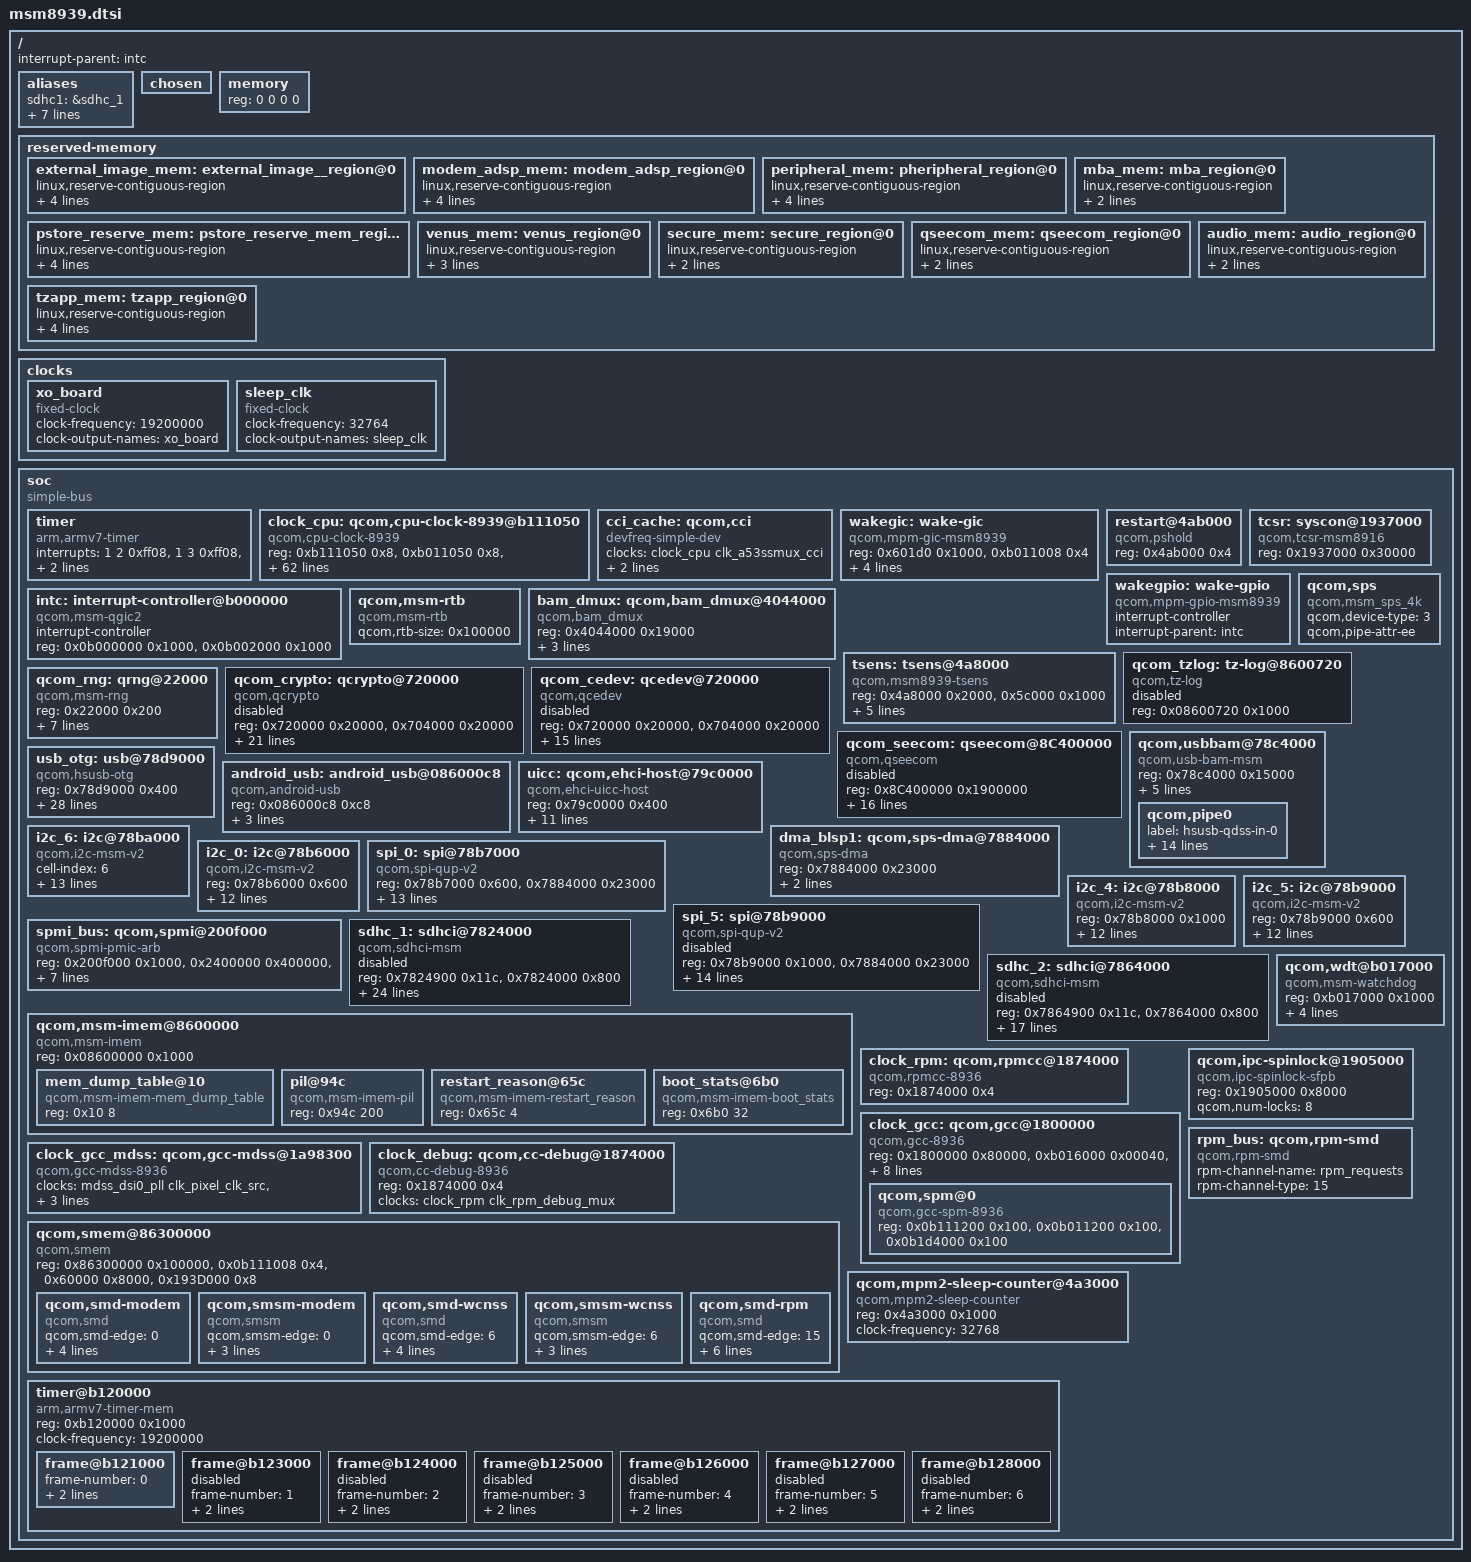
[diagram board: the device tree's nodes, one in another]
// SPDX-License-Identifier: GPL-2.0-only
/*
 * Copyright (c) 2013-2015, The Linux Foundation. All rights reserved.
 */


#include <dt-bindings/interrupt-controller/arm-gic.h>

/ {
	interrupt-parent = <&intc>;

	#address-cells = <2>;
	#size-cells = <2>;

	aliases {
		sdhc1 = &sdhc_1; /* SDC1 eMMC slot */
		sdhc2 = &sdhc_2; /* SDC2 SD card slot */
		/* smdtty devices */
		//smd0 = &smdtty_ds;
		//smd1 = &smdtty_apps_fm;
		//smd2 = &smdtty_apps_riva_bt_acl;
		//smd3 = &smdtty_apps_riva_bt_cmd;
		//smd5 = &smdtty_apps_riva_ant_cmd;
		//smd6 = &smdtty_apps_riva_ant_data;
		//smd7 = &smdtty_data1;
		//smd8 = &smdtty_data4;
		//smd11 = &smdtty_data11;
		//smd21 = &smdtty_data21;
		//smd36 = &smdtty_loopback;
		i2c0 = &i2c_0;
		i2c4 = &i2c_4;
		i2c5 = &i2c_5;
		i2c6 = &i2c_6;
		spi0 = &spi_0;
		spi5 = &spi_5;
	};

	chosen { };

	memory {
		device_type = "memory";
		/* We expect the bootloader to fill in the reg */
		reg = <0 0 0 0>;
	};

	reserved-memory {
		#address-cells = <2>;
		#size-cells = <2>;
		ranges;

		external_image_mem: external_image__region@0 {
			linux,reserve-contiguous-region;
			linux,reserve-region;
			linux,remove-completely;
			reg = <0x0 0x86000000 0x0 0x0800000>;
			label = "external_image_mem";
		};

		modem_adsp_mem: modem_adsp_region@0 {
			linux,reserve-contiguous-region;
			linux,reserve-region;
			linux,remove-completely;
			reg = <0x0 0x86800000 0x0 0x05600000>;
			label = "modem_adsp_mem";
		};

		peripheral_mem: pheripheral_region@0 {
			linux,reserve-contiguous-region;
			linux,reserve-region;
			linux,remove-completely;
			reg = <0x0 0x8be00000 0x0 0x0600000>;
			label = "peripheral_mem";
		};

		pstore_reserve_mem: pstore_reserve_mem_region@0 {
			linux,reserve-contiguous-region;
			linux,reserve-region;
			linux,remove-completely;
			reg = <0x0 0xdfe00000 0x0 0x00200000>;
			label = "pstore_reserve_mem";
		};

		mba_mem: mba_region@0 {
			linux,reserve-contiguous-region;
			reg = <0 0 0 0x0200000>;
			label = "mba_mem";
		};

		venus_mem: venus_region@0 {
			linux,reserve-contiguous-region;
			linux,memory-limit = <0x90000000>;
			reg = <0 0 0 0x0500000>;
			label = "venus_mem";
		};

		secure_mem: secure_region@0 {
			linux,reserve-contiguous-region;
			reg = <0 0 0 0x6D00000>;
			label = "secure_mem";
		};

		qseecom_mem: qseecom_region@0 {
			linux,reserve-contiguous-region;
			reg = <0 0 0 0x1900000>;
			label = "qseecom_mem";
		};

		audio_mem: audio_region@0 {
			linux,reserve-contiguous-region;
			reg = <0 0 0 0x314000>;
			label = "audio_mem";
		};

		tzapp_mem: tzapp_region@0 {
			linux,reserve-contiguous-region;
			linux,reserve-region;
			linux,remove-completely;
			reg = <0 0x8C400000 0 0x1900000>;
			label = "tzapp_mem";
		};
	};

	clocks {
		xo_board {
			compatible = "fixed-clock";
			#clock-cells = <0>;
			clock-frequency = <19200000>;
			clock-output-names = "xo_board";
		};

		sleep_clk {
			compatible = "fixed-clock";
			#clock-cells = <0>;
			clock-frequency = <32764>;
			clock-output-names = "sleep_clk";
		};
	};

	soc: soc {
		#address-cells = <1>;
		#size-cells = <1>;
		ranges = <0 0 0 0xffffffff>;
		compatible = "simple-bus";

	timer {
		compatible = "arm,armv7-timer";
		interrupts = <1 2 0xff08>,
			     <1 3 0xff08>,
			     <1 4 0xff08>,
			     <1 1 0xff08>;
		clock-frequency = <19200000>;
	};

	clock_cpu: qcom,cpu-clock-8939@b111050 {
		compatible = "qcom,cpu-clock-8939";
		reg =   <0xb111050 0x8>,
			<0xb011050 0x8>,
			<0xb1d1050 0x8>,
			<0x5800c   0x8>,
			<0x58000   0x8>,
			<0x58004   0x8>;
		reg-names = "apcs-c0-rcg-base", "apcs-c1-rcg-base",
				"apcs-cci-rcg-base", "efuse", "efuse1",
				"efuse2";
		vdd-c0-supply = <&apc_vreg_corner>;
		vdd-c1-supply = <&apc_vreg_corner>;
		vdd-cci-supply = <&apc_vreg_corner>;
		clocks = <&clock_gcc clk_gpll0_ao>,
			 <&clock_gcc clk_a53ss_c0_pll>,
			 <&clock_gcc clk_gpll0_ao>,
			 <&clock_gcc clk_a53ss_c1_pll>,
			 <&clock_gcc clk_gpll0_ao>,
			 <&clock_gcc clk_a53ss_cci_pll>;
		clock-names = "clk-c0-4", "clk-c0-5",
				"clk-c1-4", "clk-c1-5",
				"clk-cci-4", "clk-cci-5";
		qcom,speed0-bin-v0-c0 =
			<          0 0>,
			<  400000000 3>,
			<  500000000 9>,
			<  800000000 12>,
			<  998400000 17>,
			< 1113600000 20>,
			< 1209600000 21>;

		qcom,speed0-bin-v0-c1 =
			<          0 0>,
			<  400000000 3>,
			<  800000000 9>,
			<  960000000 12>,
			< 1113600000 14>,
			< 1344000000 17>;

		qcom,speed0-bin-v0-cci =
			<          0 0>,
			<  200000000 3>,
			<  300000000 9>,
			<  400000000 15>,
			<  600000000 17>;

		qcom,speed2-bin-v0-c0 =
			<          0 0>,
			<  400000000 3>,
			<  500000000 9>,
			<  800000000 12>,
			<  998400000 17>,
			< 1113600000 20>,
			< 1209600000 22>;

		qcom,speed2-bin-v0-c1 =
			<          0 0>,
			<  400000000 3>,
			<  800000000 9>,
			<  960000000 12>,
			< 1113600000 14>,
			< 1344000000 17>,
			< 1459200000 20>,
			< 1497600000 21>;

		qcom,speed2-bin-v0-cci =
			<          0 0>,
			<  200000000 3>,
			<  300000000 9>,
			<  400000000 15>,
			<  600000000 17>;

		qcom,speed2-bin-v2-c0 =
			<          0 0>,
			<  400000000 3>,
			<  500000000 9>,
			<  800000000 12>,
			<  998400000 17>,
			< 1113600000 20>,
			< 1209600000 22>;

		qcom,speed2-bin-v2-c1 =
			<          0 0>,
			<  400000000 3>,
			<  800000000 9>,
			<  960000000 12>,
			< 1113600000 14>,
			< 1344000000 17>,
			< 1459200000 20>;

		qcom,speed2-bin-v2-cci =
			<          0 0>,
			<  200000000 3>,
			<  300000000 9>,
			<  400000000 15>,
			<  600000000 17>;

		qcom,speed4-bin-v0-c0 =
			<          0 0>,
			<  400000000 3>,
			<  500000000 9>,
			<  800000000 12>,
			<  998400000 17>,
			< 1113600000 20>,
			< 1209600000 26>;

		qcom,speed4-bin-v0-c1 =
			<          0 0>,
			<  400000000 3>,
			<  800000000 9>,
			<  960000000 12>,
			< 1113600000 14>,
			< 1344000000 17>,
			< 1459200000 20>,
			< 1497600000 21>,
			< 1651200000 26>;

		qcom,speed4-bin-v0-cci =
			<          0 0>,
			<  200000000 3>,
			<  300000000 9>,
			<  400000000 15>,
			<  600000000 17>;

		qcom,speed5-bin-v0-c0 =
			<          0 0>,
			<  400000000 3>,
			<  500000000 9>,
			<  800000000 12>,
			<  998400000 17>,
			< 1113600000 20>,
			< 1209600000 23>;

		qcom,speed5-bin-v0-c1 =
			<          0 0>,
			<  400000000 3>,
			<  800000000 9>,
			<  960000000 12>,
			< 1113600000 14>,
			< 1344000000 17>,
			< 1459200000 18>,
			< 1497600000 21>,
			< 1651200000 26>;

		qcom,speed5-bin-v0-cci =
			<          0 0>,
			<  200000000 3>,
			<  300000000 9>,
			<  400000000 15>,
			<  600000000 17>;

		qcom,speed5-bin-v6-c0 =
			<          0 0>,
			<  400000000 3>,
			<  500000000 9>,
			<  800000000 12>,
			<  998400000 17>,
			< 1113600000 20>,
			< 1209600000 23>;

		qcom,speed5-bin-v6-c1 =
			<          0 0>,
			<  400000000 3>,
			<  800000000 9>,
			<  960000000 12>,
			< 1113600000 14>,
			< 1344000000 17>,
			< 1459200000 18>,
			< 1497600000 21>,
			< 1651200000 26>;

		qcom,speed5-bin-v6-cci =
			<          0 0>,
			<  200000000 3>,
			<  300000000 9>,
			<  400000000 15>,
			<  600000000 17>;

		#clock-cells = <1>;
	};

	cci_cache: qcom,cci {
		compatible = "devfreq-simple-dev";
		clock-names = "devfreq_clk";
		clocks = <&clock_cpu clk_a53ssmux_cci>;
		governor = "cpufreq";
		freq-tbl-khz =
			<  200000 >,
			<  297600 >,
			<  400000 >,
			<  595200 >;
	};
#if 0
	cpubw: qcom,cpubw {
		label = "cpubw";
		compatible = "qcom,devbw";
		governor = "cpufreq";
		qcom,src-dst-ports = <1 512>;
		qcom,active-only;
		qcom,bw-tbl =
			<  1525 /*  100   MHz */ >,
			<  2636 /*  172.8 MHz */ >,
			<  3955 /*  259.2 MHz */ >,
			<  5346 /*  350.4 MHz */ >,
			<  5712 /*  374.4 MHz */ >,
			<  6079 /*  398.4 MHz */ >;
	};

	mincpubw: qcom,mincpubw {
		label = "mincpubw";
		compatible = "qcom,devbw";
		governor = "powersave";
		qcom,src-dst-ports = <1 512>;
		qcom,active-only;
		qcom,bw-tbl =
			<  1525 /*  100   MHz */ >,
			<  2636 /*  172.8 MHz */ >,
			<  3955 /*  259.2 MHz */ >,
			<  5346 /*  350.4 MHz */ >,
			<  5712 /*  374.4 MHz */ >,
			<  6079 /*  398.4 MHz */ >;
	};

	devfreq-cpufreq {
		cpubw-cpufreq {
		target-dev = <&cpubw>;
		cpu-to-dev-map-0 =
			<  200000  1525 >,
			<  800000  2636 >,
			< 1113600  5346 >,
			< 1651200  6079 >;
		cpu-to-dev-map-4 =
			<  200000  1525 >,
			<  499200  2636 >,
			<  800000  5346 >,
			< 1209600  6079 >;
		};

		mincpubw-cpufreq {
		target-dev = <&mincpubw>;
		cpu-to-dev-map-0 =
			< 1113600 2636 >,
			< 1651200 5346 >;
		cpu-to-dev-map-4 =
			<  998400 2636 >,
			< 1209600 5346 >;
		};

		cci-cpufreq {
		target-dev = <&cci_cache>;
		cpu-to-dev-map-0 =
			<  200000  200000 >,
			<  400000  200000 >,
			< 1113600  297000 >,
			< 1651200  595200 >;
		cpu-to-dev-map-4 =
			<  200000 200000 >,
			<  400000 200000 >,
			<  800000 297600 >,
			< 1209600 595200 >;
		};
	};

	qcom,msm-cpufreq {
		compatible = "qcom,msm-cpufreq";
		clock-names = "l2_clk", "cpu0_clk", "cpu1_clk", "cpu2_clk",
				"cpu3_clk", "cpu4_clk", "cpu5_clk",
				"cpu6_clk", "cpu7_clk";
		clocks = <&clock_cpu clk_a53ssmux_cci>,
			 <&clock_cpu clk_a53ssmux_bc>,
			 <&clock_cpu clk_a53ssmux_bc>,
			 <&clock_cpu clk_a53ssmux_bc>,
			 <&clock_cpu clk_a53ssmux_bc>,
			 <&clock_cpu clk_a53ssmux_lc>,
			 <&clock_cpu clk_a53ssmux_lc>,
			 <&clock_cpu clk_a53ssmux_lc>,
			 <&clock_cpu clk_a53ssmux_lc>;

		qcom,governor-per-policy;

		qcom,cpufreq-table-0 =
			 <  200000 >,
			 <  345600 >,
			 <  400000 >,
			 <  533330 >,
			 <  800000 >,
                         <  960000 >,
			 < 1113600 >,
			 < 1344000 >,
			 < 1459200 >,
			 < 1497600 >,
			 < 1651200 >;

		qcom,cpufreq-table-4 =
			 <  200000 >,
			 <  249600 >,
			 <  400000 >,
			 <  499200 >,
			 <  800000 >,
			 <  998400 >,
			 < 1113600 >,
			 < 1209600 >;
	};

	cpu-pmu {
		compatible = "arm,armv8-pmuv3";
		qcom,irq-is-percpu;
		interrupts = <1 7 0xff00>;
	};

	jtag_fuse: jtagfuse@5e01c {
		compatible = "qcom,jtag-fuse-v2";
		reg = <0x5e01c 0x8>;
		reg-names = "fuse-base";
	};

	sn_fuse: snfuse@0x5c008 {
		compatible = "qcom,sn-fuse";
		reg = <0x5c008 0x4>;
		reg-names = "sn-base";
	};

	sec_boot_fuse: secbootfuse@0x5c098 {
		compatible = "qcom,sec-boot-fuse";
		reg = <0x5c098 0x4>;
		reg-names = "sec-boot-base";
	};
	jtag_mm0: jtagmm@8fc000 {
		compatible = "qcom,jtagv8-mm";
		reg = <0x8fc000 0x1000>,
		      <0x8f0000 0x1000>;
		reg-names = "etm-base", "debug-base";

		clocks = <&clock_rpm clk_qdss_clk>,
		         <&clock_rpm clk_qdss_a_clk>;
		clock-names = "core_clk", "core_a_clk";

		qcom,coresight-jtagmm-cpu = <&CPU0>;
	};

	jtag_mm1: jtagmm@8fd000 {
		compatible = "qcom,jtagv8-mm";
		reg = <0x8fd000 0x1000>,
		      <0x8f2000 0x1000>;
		reg-names = "etm-base", "debug-base";

		clocks = <&clock_rpm clk_qdss_clk>,
		         <&clock_rpm clk_qdss_a_clk>;
		clock-names = "core_clk", "core_a_clk";

		qcom,coresight-jtagmm-cpu = <&CPU1>;
	};

	jtag_mm2: jtagmm@8fe000 {
		compatible = "qcom,jtagv8-mm";
		reg = <0x8fe000 0x1000>,
		      <0x8f4000 0x1000>;
		reg-names = "etm-base", "debug-base";

		clocks = <&clock_rpm clk_qdss_clk>,
		         <&clock_rpm clk_qdss_a_clk>;
		clock-names = "core_clk", "core_a_clk";

		qcom,coresight-jtagmm-cpu = <&CPU2>;
	};

	jtag_mm3: jtagmm@8ff000 {
		compatible = "qcom,jtagv8-mm";
		reg = <0x8ff000 0x1000>,
		      <0x8f6000 0x1000>;
		reg-names = "etm-base", "debug-base";

		clocks = <&clock_rpm clk_qdss_clk>,
		         <&clock_rpm clk_qdss_a_clk>;
		clock-names = "core_clk", "core_a_clk";

		qcom,coresight-jtagmm-cpu = <&CPU3>;
	};

	jtag_mm4: jtagmm@8dc000 {
		compatible = "qcom,jtagv8-mm";
		reg = <0x8dc000 0x1000>,
		      <0x8d0000 0x1000>;
		reg-names = "etm-base", "debug-base";

		clocks = <&clock_rpm clk_qdss_clk>,
		         <&clock_rpm clk_qdss_a_clk>;
		clock-names = "core_clk", "core_a_clk";

		qcom,coresight-jtagmm-cpu = <&CPU4>;
	};

	jtag_mm5: jtagmm@8dd000 {
		compatible = "qcom,jtagv8-mm";
		reg = <0x8dd000 0x1000>,
		      <0x8d2000 0x1000>;
		reg-names = "etm-base", "debug-base";

		clocks = <&clock_rpm clk_qdss_clk>,
		         <&clock_rpm clk_qdss_a_clk>;
		clock-names = "core_clk", "core_a_clk";

		qcom,coresight-jtagmm-cpu = <&CPU5>;
	};

	jtag_mm6: jtagmm@8de000 {
		compatible = "qcom,jtagv8-mm";
		reg = <0x8de000 0x1000>,
		      <0x8d4000 0x1000>;
		reg-names = "etm-base", "debug-base";

		clocks = <&clock_rpm clk_qdss_clk>,
		         <&clock_rpm clk_qdss_a_clk>;
		clock-names = "core_clk", "core_a_clk";

		qcom,coresight-jtagmm-cpu = <&CPU6>;
	};

	jtag_mm7: jtagmm@8df000 {
		compatible = "qcom,jtagv8-mm";
		reg = <0x8df000 0x1000>,
		      <0x8d6000 0x1000>;
		reg-names = "etm-base", "debug-base";

		clocks = <&clock_rpm clk_qdss_clk>,
		         <&clock_rpm clk_qdss_a_clk>;
		clock-names = "core_clk", "core_a_clk";

		qcom,coresight-jtagmm-cpu = <&CPU7>;
	};

	qcom,msm-thermal {
		qcom,core-control-mask = <0xFF>;
		qcom,freq-mitigation-control-mask = <0xFF>;
	};
#endif
	wakegic: wake-gic {
		compatible = "qcom,mpm-gic-msm8939", "qcom,mpm-gic";
		reg = <0x601d0 0x1000>, /* MSM_RPM_MPM_BASE 4K */
		      <0xb011008 0x4>;
		reg-names = "vmpm", "ipc";
		qcom,num-mpm-irqs = <96>;
		interrupts = <GIC_SPI 171 IRQ_TYPE_EDGE_RISING>;
		interrupt-controller;
		interrupt-parent = <&intc>;
		#interrupt-cells = <3>;
	};

	restart@4ab000 {
		compatible = "qcom,pshold";
		reg = <0x4ab000 0x4>;
		reg-names = "pshold-base";
	};

	tcsr: syscon@1937000 {
		compatible = "qcom,tcsr-msm8916", "syscon";
		reg = <0x1937000 0x30000>;
		};

	wakegpio: wake-gpio {
		compatible = "qcom,mpm-gpio-msm8939", "qcom,mpm-gpio";
		interrupt-controller;
		interrupt-parent = <&intc>;
		#interrupt-cells = <2>;
	};

	intc: interrupt-controller@b000000 {
			compatible = "qcom,msm-qgic2";
			interrupt-controller;
			#interrupt-cells = <3>;
			reg = <0x0b000000 0x1000>, <0x0b002000 0x1000>;
		};

	qcom,msm-rtb {
		compatible = "qcom,msm-rtb";
		qcom,rtb-size = <0x100000>;
	};

	qcom,sps {
		compatible = "qcom,msm_sps_4k";
		qcom,device-type = <3>;
		qcom,pipe-attr-ee;
	};

	bam_dmux: qcom,bam_dmux@4044000 {
		compatible = "qcom,bam_dmux";
		reg = <0x4044000 0x19000>;
		interrupts = <0 29 1>;
		qcom,rx-ring-size = <32>;
		qcom,max-rx-mtu = <4096>;
	};

	tsens: tsens@4a8000 {
		compatible = "qcom,msm8939-tsens";
		reg = <0x4a8000 0x2000>,
		      <0x5c000  0x1000>;
		reg-names = "tsens_physical", "tsens_eeprom_physical";
		interrupts = <0 184 0>;
		interrupt-names = "tsens-upper-lower";
		qcom,sensors = <9>;
		qcom,slope = <2911 2789 2906 2763 2922 2867 2833 2838 2840>;
		qcom,sensor-id = <0 1 2 3 5 6 7 8 9>;
	};

	qcom_tzlog: tz-log@8600720 {
		compatible = "qcom,tz-log";
		reg = <0x08600720 0x1000>;
		status = "disabled";
	};

	qcom_rng: qrng@22000 {
		compatible = "qcom,msm-rng";
		reg = <0x22000 0x200>;
		qcom,msm-rng-iface-clk;
		qcom,msm-bus,name = "msm-rng-noc";
		qcom,msm-bus,num-cases = <2>;
		qcom,msm-bus,num-paths = <1>;
		qcom,msm-bus,vectors-KBps =
				<1 618 0 0>,		/* No vote */
				<1 618 0 800>;		/* 100 MB/s */
		clocks = <&clock_gcc clk_gcc_prng_ahb_clk>;
		clock-names = "iface_clk";
		status = "ok";
	};

	qcom_crypto: qcrypto@720000 {
		compatible = "qcom,qcrypto";
		reg = <0x720000 0x20000>,
		      <0x704000 0x20000>;
		reg-names = "crypto-base","crypto-bam-base";
		interrupts = <0 207 0>;
		qcom,bam-pipe-pair = <2>;
		qcom,ce-hw-instance = <0>;
		qcom,ce-device = <0>;
		qcom,clk-mgmt-sus-res;
		qcom,msm-bus,name = "qcrypto-noc";
		qcom,msm-bus,num-cases = <2>;
		qcom,msm-bus,num-paths = <1>;
		qcom,msm-bus,vectors-KBps =
				<55 512 0 0>,
				<55 512 393600 800000>; /* 49.2MHz & 100MHz */
		clocks = <&clock_gcc clk_crypto_clk_src>,
			 <&clock_gcc clk_gcc_crypto_clk>,
			 <&clock_gcc clk_gcc_crypto_ahb_clk>,
			 <&clock_gcc clk_gcc_crypto_axi_clk>;
		clock-names = "core_clk_src", "core_clk",
				"iface_clk", "bus_clk";
                qcom,use-sw-aes-cbc-ecb-ctr-algo;
                qcom,use-sw-aes-xts-algo;
                qcom,use-sw-aes-ccm-algo;
                qcom,use-sw-ahash-algo;
		qcom,use-sw-hmac-algo;
		qcom,use-sw-aead-algo;
		status = "disabled";
		qcom,ce-opp-freq = <100000000>;
	};

	qcom_cedev: qcedev@720000 {
		compatible = "qcom,qcedev";
		reg = <0x720000 0x20000>,
		      <0x704000 0x20000>;
		reg-names = "crypto-base","crypto-bam-base";
		interrupts = <0 207 0>;
		qcom,bam-pipe-pair = <1>;
		qcom,ce-hw-instance = <0>;
		qcom,ce-device = <0>;
		qcom,ce-hw-shared;
		qcom,msm-bus,name = "qcedev-noc";
		qcom,msm-bus,num-cases = <2>;
		qcom,msm-bus,num-paths = <1>;
		qcom,msm-bus,vectors-KBps =
				<55 512 0 0>,
				<55 512 393600 800000>; /* 49.2MHz & 100MHz */
		clocks = <&clock_gcc clk_crypto_clk_src>,
			 <&clock_gcc clk_gcc_crypto_clk>,
			 <&clock_gcc clk_gcc_crypto_ahb_clk>,
			 <&clock_gcc clk_gcc_crypto_axi_clk>;
		clock-names = "core_clk_src", "core_clk",
				"iface_clk", "bus_clk";
		status = "disabled";
		qcom,ce-opp-freq = <100000000>;
	};

	qcom_seecom: qseecom@8C400000 {
		compatible = "qcom,qseecom";
		reg = <0x8C400000 0x1900000>;
		reg-names = "secapp-region";
		qcom,disk-encrypt-pipe-pair = <2>;
		qcom,hlos-ce-hw-instance = <0>;
		qcom,qsee-ce-hw-instance = <0>;
		qcom,msm-bus,name = "qseecom-noc";
		qcom,msm-bus,num-cases = <4>;
		qcom,msm-bus,num-paths = <1>;
		qcom,support-bus-scaling;
		qcom,support-fde;
		qcom,msm-bus,vectors-KBps =
				<55 512 0 0>,
				<55 512 0 0>,
				<55 512 120000 1200000>,
				<55 512 393600 3936000>;
		clocks = <&clock_gcc clk_crypto_clk_src>,
			 <&clock_gcc clk_gcc_crypto_clk>,
			 <&clock_gcc clk_gcc_crypto_ahb_clk>,
			 <&clock_gcc clk_gcc_crypto_axi_clk>;
		clock-names = "core_clk_src", "core_clk",
				"iface_clk", "bus_clk";
		status = "disabled";
		qcom,ce-opp-freq = <100000000>;
	};

	qcom,usbbam@78c4000 {
		compatible = "qcom,usb-bam-msm";
		reg = <0x78c4000 0x15000>;
		reg-names = "hsusb";
		interrupts = <0 135 0>;
		interrupt-names = "hsusb";
		qcom,usb-bam-num-pipes = <2>;
		qcom,usb-bam-fifo-baseaddr = <0x08603800>;
		qcom,ignore-core-reset-ack;
		qcom,disable-clk-gating;

		qcom,pipe0 {
			label = "hsusb-qdss-in-0";
			qcom,usb-bam-mem-type = <3>;
			qcom,bam-type = <1>;
			qcom,dir = <1>;
			qcom,pipe-num = <0>;
			qcom,peer-bam = <1>;
			qcom,src-bam-physical-address = <0x884000>;
			qcom,src-bam-pipe-index = <0>;
			qcom,dst-bam-physical-address = <0x78c4000>;
			qcom,dst-bam-pipe-index = <0>;
			qcom,data-fifo-offset = <0x0>;
			qcom,data-fifo-size = <0x600>;
			qcom,descriptor-fifo-offset = <0x600>;
			qcom,descriptor-fifo-size = <0x200>;
			qcom,reset-bam-on-connect;
		};
	};

	usb_otg: usb@78d9000 {
		compatible = "qcom,hsusb-otg";

		reg = <0x78d9000 0x400>;
		reg-names = "core";
		interrupts = <0 134 0>,<0 140 0>;
		interrupt-names = "core_irq", "async_irq";

		hsusb_vdd_dig-supply = <&pm8916_s2_corner>;
		HSUSB_1p8-supply = <&pm8916_l7>;
		HSUSB_3p3-supply = <&pm8916_l13>;
		qcom,vdd-voltage-level = <1 5 7>;

		qcom,hsusb-otg-phy-init-seq =
			<0x44 0x80 0x6B 0x81 0x24 0x82 0x13 0x83 0xffffffff>;
		qcom,hsusb-otg-phy-type = <2>;
		qcom,hsusb-otg-mode = <1>;
		qcom,hsusb-otg-otg-control = <2>;
		qcom,hsusb-otg-disable-reset;
		qcom,dp-manual-pullup;
		qcom,hsusb-otg-mpm-dpsehv-int = <49>;
		qcom,hsusb-otg-mpm-dmsehv-int = <58>;

		qcom,msm-bus,name = "usb2";
		qcom,msm-bus,num-cases = <3>;
		qcom,msm-bus,num-paths = <1>;
		qcom,msm-bus,vectors-KBps =
				<87 512 0 0>,
				<87 512 80000 0>,
				<87 512 6000  6000>;
		clocks = <&clock_gcc clk_gcc_usb_hs_ahb_clk>,
			 <&clock_gcc clk_gcc_usb_hs_system_clk>,
			 <&clock_gcc clk_gcc_usb2a_phy_sleep_clk>,
			 <&clock_rpm clk_bimc_usb_a_clk>,
			 <&clock_rpm clk_snoc_usb_a_clk>,
			 <&clock_rpm clk_pcnoc_usb_a_clk>,
			 <&clock_rpm clk_xo_otg_clk>;
		clock-names = "iface_clk", "core_clk", "sleep_clk",
				"bimc_clk", "snoc_clk", "pcnoc_clk",
				"xo";
		qcom,bus-clk-rate = <331200000 200000000 100000000>;
	};

	android_usb: android_usb@086000c8 {
		compatible = "qcom,android-usb";
		reg = <0x086000c8 0xc8>;
		qcom,pm-qos-latency = <2 1001 12701>;
		qcom,streaming-func = "rndis","mtp";
		qcom,android-usb-uicc-nluns = /bits/ 8 <1>;
	};

	uicc: qcom,ehci-host@79c0000 {
		compatible = "qcom,ehci-uicc-host";
		reg = <0x79c0000 0x400>;
		interrupts = <0 132 0>;

		clocks = <&clock_gcc clk_gcc_usb_fs_ahb_clk>,
			 <&clock_gcc clk_gcc_usb_fs_system_clk>,
			 <&clock_gcc clk_gcc_usb_fs_ic_clk>;
		clock-names = "iface_clk", "core_clk", "alt_core_clk";

                pinctrl-names = "uicc_active", "uicc_sleep";
                pinctrl-0 = <&uicc_active>;
                pinctrl-1 = <&uicc_sleep>;

		qcom,msm-bus,name = "uicc";
		qcom,msm-bus,num-cases = <2>;
		qcom,msm-bus,num-paths = <1>;
		qcom,msm-bus,vectors-KBps =
				<93 512 0 0>,
				<93 512 12000 192000>;
	};

	dma_blsp1: qcom,sps-dma@7884000 { /* BLSP1 */
		#dma-cells = <4>;
		compatible = "qcom,sps-dma";
		reg = <0x7884000 0x23000>;
		interrupts = <0 238 0>;
		qcom,summing-threshold = <10>;
	};

	i2c_6: i2c@78ba000 { /* BLSP1 QUP6 */
		compatible = "qcom,i2c-msm-v2";
		#address-cells=<1>;
		#size-cells=<0>;
		cell-index = <6>;
		reg-names = "qup_phys_addr";
		reg = <0x78ba000 0x1000>;
		interrupt-names = "qup_irq";
		interrupts = <0 100 0>;
		clocks = <&clock_gcc clk_gcc_blsp1_ahb_clk>,
			 <&clock_gcc clk_gcc_blsp1_qup6_i2c_apps_clk>;
		clock-names = "iface_clk", "core_clk";
		qcom,clk-freq-out = <400000>;
		qcom,clk-freq-in  = <19200000>;
		pinctrl-names = "i2c_active", "i2c_sleep";
		pinctrl-0 = <&i2c_6_active>;
		pinctrl-1 = <&i2c_6_sleep>;
		qcom,noise-rjct-scl = <0>;
		qcom,noise-rjct-sda = <0>;
		dmas = <&dma_blsp1 14 64 0x20000020 0x20>,
			<&dma_blsp1 15 32 0x20000020 0x20>;
		dma-names = "tx", "rx";
		qcom,master-id = <86>;
	};

	i2c_0: i2c@78b6000 { /* BLSP1 QUP2 */
		compatible = "qcom,i2c-msm-v2";
		#address-cells = <1>;
		#size-cells = <0>;
		reg-names = "qup_phys_addr";
		reg = <0x78b6000 0x600>;
		interrupt-names = "qup_irq";
		interrupts = <0 96 0>;
		clocks = <&clock_gcc clk_gcc_blsp1_ahb_clk>,
			 <&clock_gcc clk_gcc_blsp1_qup2_i2c_apps_clk>;
		clock-names = "iface_clk", "core_clk";
		qcom,clk-freq-out = <100000>;
		qcom,clk-freq-in  = <19200000>;
		pinctrl-names = "i2c_active", "i2c_sleep";
		pinctrl-0 = <&i2c_0_active>;
		pinctrl-1 = <&i2c_0_sleep>;
		qcom,noise-rjct-scl = <0>;
		qcom,noise-rjct-sda = <0>;
		dmas = <&dma_blsp1 6 64 0x20000020 0x20>,
			<&dma_blsp1 7 32 0x20000020 0x20>;
		dma-names = "tx", "rx";
		qcom,master-id = <86>;
	};

	spi_0: spi@78b7000 { /* BLSP1 QUP3 */
		compatible = "qcom,spi-qup-v2";
		#address-cells = <1>;
		#size-cells = <0>;
		reg-names = "spi_physical", "spi_bam_physical";
		reg = <0x78b7000 0x600>,
			<0x7884000 0x23000>;
		interrupt-names = "spi_irq", "spi_bam_irq";
		interrupts = <0 97 0>, <0 238 0>;
		spi-max-frequency = <19200000>;
		pinctrl-names = "spi_default", "spi_sleep";
		pinctrl-0 = <&spi0_default &spi0_cs0_active>;
		pinctrl-1 = <&spi0_sleep &spi0_cs0_sleep>;
		clocks = <&clock_gcc clk_gcc_blsp1_ahb_clk>,
			<&clock_gcc clk_gcc_blsp1_qup3_spi_apps_clk>;
		clock-names = "iface_clk", "core_clk";
		qcom,infinite-mode = <0>;
		qcom,use-bam;
		qcom,use-pinctrl;
		qcom,ver-reg-exists;
		qcom,bam-consumer-pipe-index = <8>;
		qcom,bam-producer-pipe-index = <9>;
		qcom,master-id = <86>;
		};

	i2c_4: i2c@78b8000 { /* BLSP1 QUP4 */
		compatible = "qcom,i2c-msm-v2";
		#address-cells = <1>;
		#size-cells = <0>;
		reg-names = "qup_phys_addr";
		reg = <0x78b8000 0x1000>;
		interrupt-names = "qup_irq";
		interrupts = <0 98 0>;
		qcom,clk-freq-out = <100000>;
		qcom,clk-freq-in  = <19200000>;
		clock-names = "iface_clk", "core_clk";
		clocks = <&clock_gcc clk_gcc_blsp1_ahb_clk>,
			 <&clock_gcc clk_gcc_blsp1_qup4_i2c_apps_clk>;

		pinctrl-names = "i2c_active", "i2c_sleep";
		pinctrl-0 = <&i2c_4_active>;
		pinctrl-1 = <&i2c_4_sleep>;
		qcom,noise-rjct-scl = <0>;
		qcom,noise-rjct-sda = <0>;
		dmas = <&dma_blsp1 10 64 0x20000020 0x20>,
			<&dma_blsp1 11 32 0x20000020 0x20>;
		dma-names = "tx", "rx";
		qcom,master-id = <86>;
	};

	i2c_5: i2c@78b9000 { /* BLSP1 QUP5 */
		compatible = "qcom,i2c-msm-v2";
		#address-cells = <1>;
		#size-cells = <0>;
		reg-names = "qup_phys_addr";
		reg = <0x78b9000 0x600>;
		interrupt-names = "qup_irq";
		interrupts = <0 99 0>;
		qcom,clk-freq-out = <100000>;
		qcom,clk-freq-in  = <19200000>;
		clock-names = "iface_clk", "core_clk";
		clocks = <&clock_gcc clk_gcc_blsp1_ahb_clk>,
			 <&clock_gcc clk_gcc_blsp1_qup5_i2c_apps_clk>;

		pinctrl-names = "i2c_active", "i2c_sleep";
		pinctrl-0 = <&i2c_5_active>;
		pinctrl-1 = <&i2c_5_sleep>;
		qcom,noise-rjct-scl = <0>;
		qcom,noise-rjct-sda = <0>;
		dmas = <&dma_blsp1 12 64 0x20000020 0x20>,
			<&dma_blsp1 13 32 0x20000020 0x20>;
		dma-names = "tx", "rx";
		qcom,master-id = <86>;
	};

	spi_5: spi@78b9000 {  /* BLSP1 QUP5 */
		compatible = "qcom,spi-qup-v2";
		#address-cells = <1>;
		#size-cells = <0>;
		reg-names = "spi_physical", "spi_bam_physical";
		reg = <0x78b9000 0x1000>,
			<0x7884000 0x23000>;
		interrupt-names = "spi_irq", "spi_bam_irq";
		interrupts = <0 99 0>, <0 238 0>;
		spi-max-frequency = <18000000>;
		qcom,use-pinctrl;
		pinctrl-names = "spi_default", "spi_sleep";
		pinctrl-0 = <&spi5_default &spi5_cs0_active>;
		pinctrl-1 = <&spi5_sleep &spi5_cs0_sleep>;
		clocks = <&clock_gcc clk_gcc_blsp1_ahb_clk>,
			<&clock_gcc clk_gcc_blsp1_qup5_spi_apps_clk>;
		clock-names = "iface_clk", "core_clk";
		qcom,infinite-mode = <0>;
		qcom,use-bam;
		qcom,ver-reg-exists;
		qcom,bam-consumer-pipe-index = <12>;
		qcom,bam-producer-pipe-index = <13>;
		qcom,master-id = <86>;
		qcom,rt-priority;
		status = "disabled";
	};

	spmi_bus: qcom,spmi@200f000 {
		compatible = "qcom,spmi-pmic-arb";
		reg = <0x200f000 0x1000>,
			<0x2400000 0x400000>,
			<0x2c00000 0x400000>,
			<0x3800000 0x200000>,
			<0x200a000 0x2100>;
		reg-names = "core", "chnls", "obsrvr", "intr", "cnfg";
		interrupts = <0 190 0>;
		qcom,pmic-arb-channel = <0>;
		qcom,pmic-arb-ee = <0>;
		#interrupt-cells = <3>;
		interrupt-controller;
		#address-cells = <1>;
		#size-cells = <0>;
		cell-index = <0>;
	};

	sdhc_1: sdhci@7824000 {
		compatible = "qcom,sdhci-msm";
		reg = <0x7824900 0x11c>, <0x7824000 0x800>;
		reg-names = "hc_mem", "core_mem";

		interrupts = <0 123 0>, <0 138 0>;
		interrupt-names = "hc_irq", "pwr_irq";

		qcom,bus-width = <8>;

		qcom,qos-planes = <3>;
		qcom,cpu-dma-latency-us = <2 401 701>;
		qcom,cpu-dma-latency-us-r = <2 401 701>;
		qcom,cpu-dma-latency-us-w = <2 401 701>;
		qcom,cpu-affinity-r = "affine_cores";
		qcom,cpu-affinity-mask-r = <0xf0>;
		qcom,modified-dynamic-qos;

		qcom,msm-bus,name = "sdhc1";
		qcom,msm-bus,num-cases = <8>;
		qcom,msm-bus,num-paths = <1>;
		qcom,msm-bus,vectors-KBps = <78 512 0 0>, /* No vote */
				<78 512 1600 3200>,    /* 400 KB/s*/
				<78 512 80000 160000>, /* 20 MB/s */
				<78 512 100000 200000>, /* 25 MB/s */
				<78 512 200000 400000>, /* 50 MB/s */
				<78 512 400000 800000>, /* 100 MB/s */
				<78 512 400000 800000>, /* 200 MB/s */
				<78 512 2048000 4096000>; /* Max. bandwidth */
		qcom,bus-bw-vectors-bps = <0 400000 20000000 25000000 50000000
						100000000 200000000 4294967295>;

		clocks = <&clock_gcc clk_gcc_sdcc1_ahb_clk>,
			 <&clock_gcc clk_gcc_sdcc1_apps_clk>;
		clock-names = "iface_clk", "core_clk";

		qcom,clk-rates = <400000 25000000 50000000 100000000 177770000>;
		qcom,bus-speed-mode = "HS200_1p8v", "DDR_1p8v";

		status = "disabled";
	};

	sdhc_2: sdhci@7864000 {
		compatible = "qcom,sdhci-msm";
		reg = <0x7864900 0x11c>, <0x7864000 0x800>;
		reg-names = "hc_mem", "core_mem";

		interrupts = <0 125 0>, <0 221 0>;
		interrupt-names = "hc_irq", "pwr_irq";

		qcom,bus-width = <4>;
		qcom,cpu-dma-latency-us = <401>;
		qcom,msm-bus,name = "sdhc2";
		qcom,msm-bus,num-cases = <8>;
		qcom,msm-bus,num-paths = <1>;
		qcom,msm-bus,vectors-KBps = <81 512 0 0>, /* No vote */
				<81 512 1600 3200>,    /* 400 KB/s*/
				<81 512 80000 160000>, /* 20 MB/s */
				<81 512 100000 200000>, /* 25 MB/s */
				<81 512 200000 400000>, /* 50 MB/s */
				<81 512 400000 800000>, /* 100 MB/s */
				<81 512 400000 800000>, /* 200 MB/s */
				<81 512 2048000 4096000>; /* Max. bandwidth */
		qcom,bus-bw-vectors-bps = <0 400000 20000000 25000000 50000000
						100000000 200000000 4294967295>;

		clocks = <&clock_gcc clk_gcc_sdcc2_ahb_clk>,
			 <&clock_gcc clk_gcc_sdcc2_apps_clk>;
		clock-names = "iface_clk", "core_clk";

		qcom,clk-rates = <400000 25000000 50000000 100000000 200000000>;

		status = "disabled";
	};

	qcom,msm-imem@8600000 {
		compatible = "qcom,msm-imem";
		reg = <0x08600000 0x1000>; /* Address and size of IMEM */
		ranges = <0x0 0x08600000 0x1000>;
		#address-cells = <1>;
		#size-cells = <1>;

		mem_dump_table@10 {
			compatible = "qcom,msm-imem-mem_dump_table";
			reg = <0x10 8>;
		};

		pil@94c {
			compatible = "qcom,msm-imem-pil";
			reg = <0x94c 200>;
		};

		restart_reason@65c {
			compatible = "qcom,msm-imem-restart_reason";
			reg = <0x65c 4>;
		};

		boot_stats@6b0 {
			compatible = "qcom,msm-imem-boot_stats";
			reg = <0x6b0 32>;
		};
	};

	clock_rpm: qcom,rpmcc@1874000 {
			compatible = "qcom,rpmcc-8936";
			reg = <0x1874000 0x4>;
			reg-names = "cc_base";
			#clock-cells = <1>;
		};

	clock_gcc: qcom,gcc@1800000 {
		compatible = "qcom,gcc-8936";
		reg = <0x1800000 0x80000>,
			<0xb016000 0x00040>,
			<0xb116000 0x00040>,
			<0xb1d0000 0x00040>;
		reg-names = "cc_base", "apcs_c1_base",
				"apcs_c0_base", "apcs_cci_base";
		vdd_dig-supply = <&pm8916_s2_corner>;
		vdd_sr2_dig-supply = <&pm8916_s2_corner_ao>;
		vdd_sr2_pll-supply = <&pm8916_l7_ao>;
		vdd_hf_dig-supply = <&pm8916_s2_corner_ao>;
		vdd_hf_pll-supply = <&pm8916_l7_ao>;
		clocks = <&clock_rpm clk_xo_clk_src>,
                         <&clock_rpm clk_xo_a_clk_src>;
		#address-cells = <1>;
		#size-cells = <1>;
		clock-names = "xo", "xo_a";
		#clock-cells = <1>;
		ranges;
		qcom,spm@0 {
			compatible = "qcom,gcc-spm-8936";
			reg = <0x0b111200 0x100>,
			      <0x0b011200 0x100>,
			      <0x0b1d4000 0x100>;
			reg-names = "spm_c0_base", "spm_c1_base", "spm_cci_base";
		};
	};

	clock_gcc_mdss: qcom,gcc-mdss@1a98300 {
		compatible = "qcom,gcc-mdss-8936";
		clocks = <&mdss_dsi0_pll clk_pixel_clk_src>,
			 <&mdss_dsi0_pll clk_byte_clk_src>,
			 <&mdss_dsi0_pll clk_pixel_clk_src>,
			 <&mdss_dsi0_pll clk_byte_clk_src>;
		clock-names = "pclk0_src", "byte0_src", "pclk1_src",
				 "byte1_src";
		#clock-cells = <1>;
	};

	clock_debug: qcom,cc-debug@1874000 {
		compatible = "qcom,cc-debug-8936";
		reg = <0x1874000 0x4>;
		reg-names = "cc_base";
		clocks = <&clock_rpm clk_rpm_debug_mux>;
		clock-names = "rpm_debug_mux";
		#clock-cells = <1>;
	};

	qcom,wdt@b017000 {
		compatible = "qcom,msm-watchdog";
		reg = <0xb017000 0x1000>;
		reg-names = "wdt-base";
		interrupts = <0 3 0>, <0 4 0>;
		qcom,bark-time = <11000>;
		qcom,pet-time = <10000>;
		qcom,ipi-ping;
	};

	qcom,ipc-spinlock@1905000 {
		compatible = "qcom,ipc-spinlock-sfpb";
		reg = <0x1905000 0x8000>;
		qcom,num-locks = <8>;
	};

	qcom,smem@86300000 {
		compatible = "qcom,smem";
		reg = <0x86300000 0x100000>,
			<0x0b111008 0x4>,
			<0x60000 0x8000>,
			<0x193D000 0x8>;
		reg-names = "smem", "irq-reg-base", "aux-mem1", "smem_targ_info_reg";
		//qcom,mpu-enabled;


		qcom,smd-modem {
			compatible = "qcom,smd";
			qcom,smd-edge = <0>;
			qcom,smd-irq-offset = <0x0>;
			qcom,smd-irq-bitmask = <0x1000>;
			interrupts = <0 25 1>;
			label = "modem";
		};

		qcom,smsm-modem {
			compatible = "qcom,smsm";
			qcom,smsm-edge = <0>;
			qcom,smsm-irq-offset = <0x0>;
			qcom,smsm-irq-bitmask = <0x2000>;
			interrupts = <0 26 1>;
		};

		qcom,smd-wcnss {
			compatible = "qcom,smd";
			qcom,smd-edge = <6>;
			qcom,smd-irq-offset = <0x0>;
			qcom,smd-irq-bitmask = <0x20000>;
			interrupts = <0 142 1>;
			label = "wcnss";
		};

		qcom,smsm-wcnss {
			compatible = "qcom,smsm";
			qcom,smsm-edge = <6>;
			qcom,smsm-irq-offset = <0x0>;
			qcom,smsm-irq-bitmask = <0x80000>;
			interrupts = <0 144 1>;
		};

		qcom,smd-rpm {
			compatible = "qcom,smd";
			qcom,smd-edge = <15>;
			qcom,smd-irq-offset = <0x0>;
			qcom,smd-irq-bitmask = <0x1>;
			interrupts = <0 168 1>;
			label = "rpm";
			qcom,irq-no-suspend;
			qcom,not-loadable;
		};
	};

	qcom,mpm2-sleep-counter@4a3000 {
		compatible = "qcom,mpm2-sleep-counter";
		reg = <0x4a3000 0x1000>;
		clock-frequency = <32768>;
	};

        rpm_bus: qcom,rpm-smd {
                compatible = "qcom,rpm-smd";
                rpm-channel-name = "rpm_requests";
                rpm-channel-type = <15>; /* SMD_APPS_RPM */
        };

	timer@b120000 {
		#address-cells = <1>;
		#size-cells = <1>;
		ranges;
		compatible = "arm,armv7-timer-mem";
		reg = <0xb120000 0x1000>;
		clock-frequency = <19200000>;

		frame@b121000 {
			frame-number = <0>;
			interrupts = <0 8 0x4>,
				     <0 7 0x4>;
			reg = <0xb121000 0x1000>,
			      <0xb122000 0x1000>;
		};

		frame@b123000 {
			frame-number = <1>;
			interrupts = <0 9 0x4>;
			reg = <0xb123000 0x1000>;
			status = "disabled";
		};

		frame@b124000 {
			frame-number = <2>;
			interrupts = <0 10 0x4>;
			reg = <0xb124000 0x1000>;
			status = "disabled";
		};

		frame@b125000 {
			frame-number = <3>;
			interrupts = <0 11 0x4>;
			reg = <0xb125000 0x1000>;
			status = "disabled";
		};

		frame@b126000 {
			frame-number = <4>;
			interrupts = <0 12 0x4>;
			reg = <0xb126000 0x1000>;
			status = "disabled";
		};

		frame@b127000 {
			frame-number = <5>;
			interrupts = <0 13 0x4>;
			reg = <0xb127000 0x1000>;
			status = "disabled";
		};

		frame@b128000 {
			frame-number = <6>;
			interrupts = <0 14 0x4>;
			reg = <0xb128000 0x1000>;
			status = "disabled";
			};
		};
	};
};
#include "../msm-pm8916-rpm-regulator.dtsi"
#include "../msm-pm8916.dtsi"
#include "../msm8939-regulator.dtsi"
